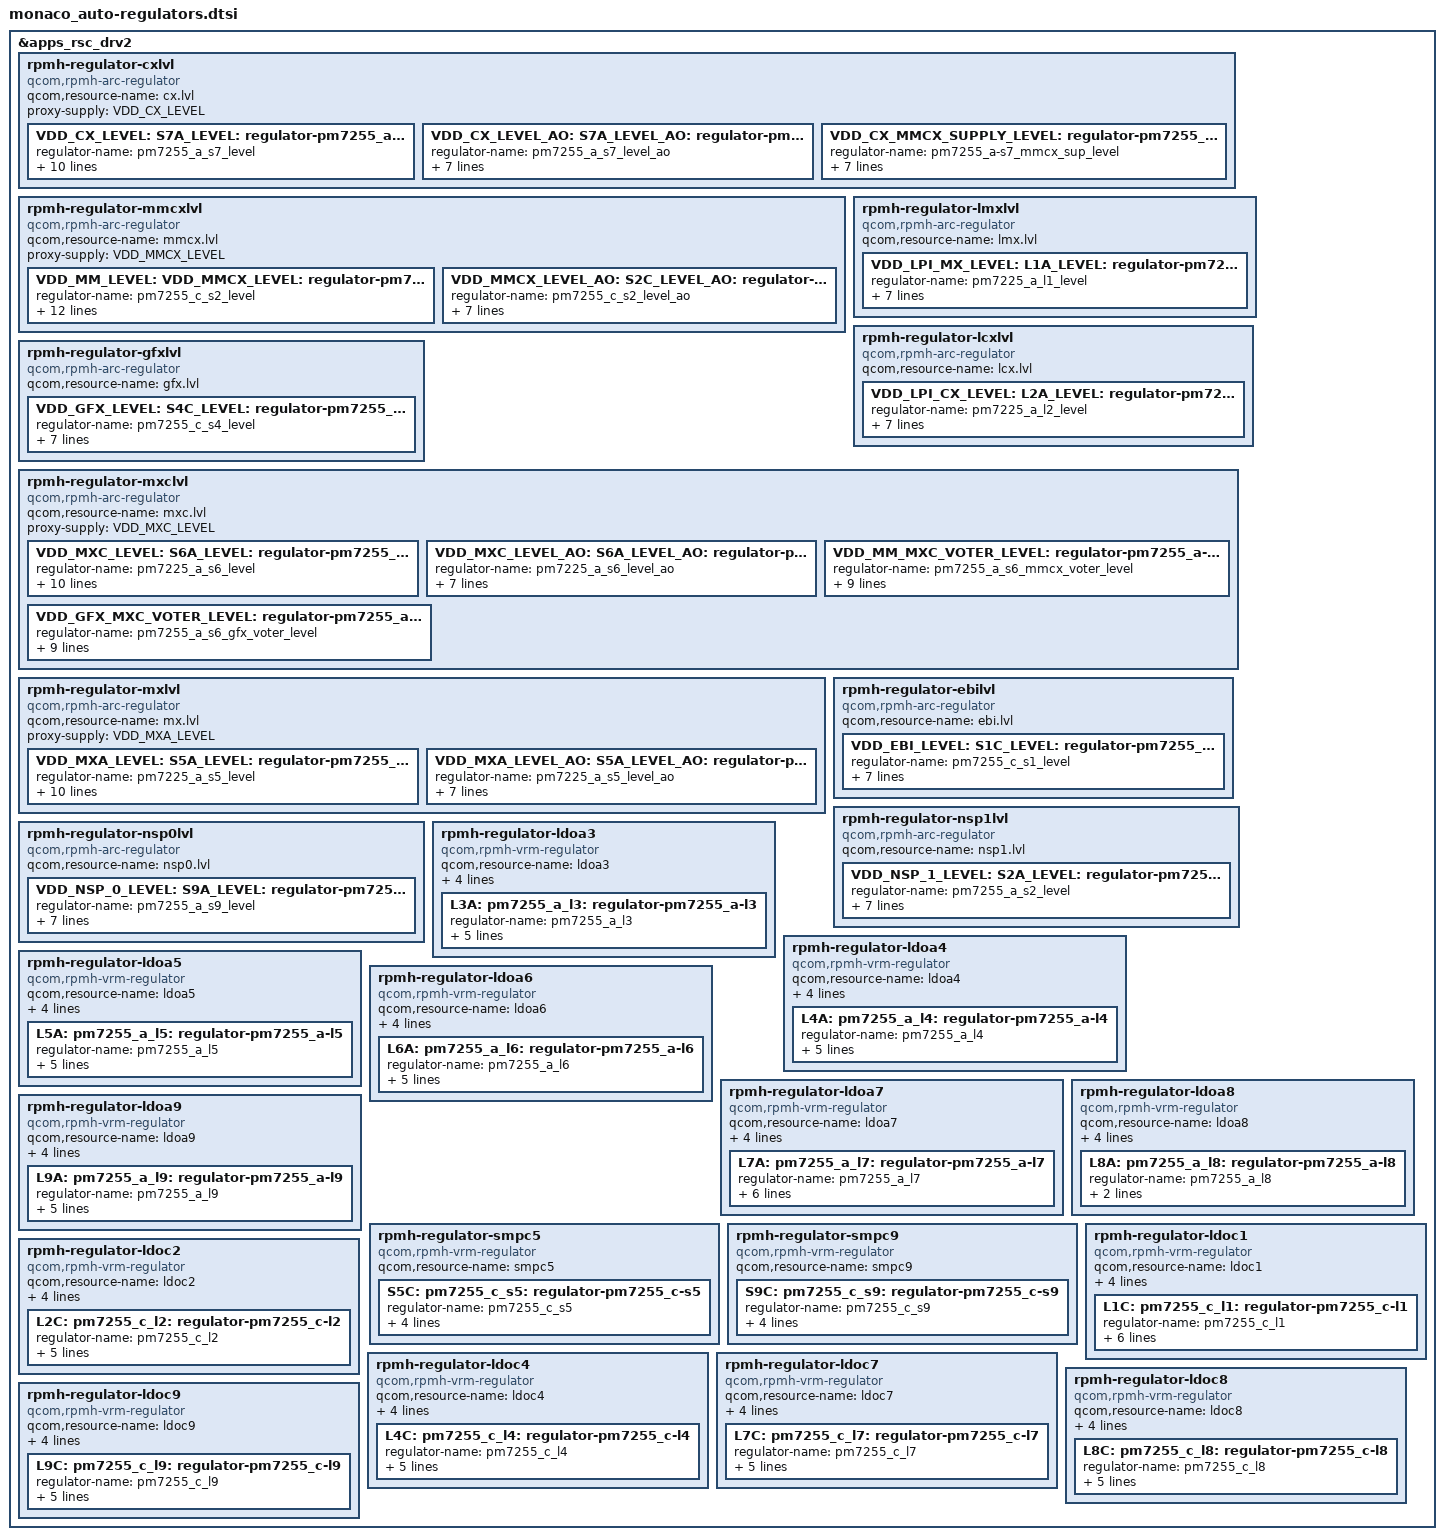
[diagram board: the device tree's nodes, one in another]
#include <dt-bindings/regulator/qcom,rpmh-regulator-levels.h>

&apps_rsc_drv2 {

	rpmh-regulator-cxlvl {
		compatible = "qcom,rpmh-arc-regulator";
		qcom,resource-name = "cx.lvl";
		proxy-supply = <&VDD_CX_LEVEL>;

		VDD_CX_LEVEL: S7A_LEVEL:
		pm7255_a_s7_level: regulator-pm7255_a-s7-level {
			regulator-name = "pm7255_a_s7_level";
			qcom,set = <RPMH_REGULATOR_SET_ALL>;
			regulator-min-microvolt =
				<RPMH_REGULATOR_LEVEL_RETENTION>;
			regulator-max-microvolt =
				<RPMH_REGULATOR_LEVEL_MAX>;
			qcom,init-voltage-level =
				<RPMH_REGULATOR_LEVEL_TURBO>;
			qcom,proxy-consumer-enable;
			qcom,proxy-consumer-voltage =
				<RPMH_REGULATOR_LEVEL_TURBO
				 RPMH_REGULATOR_LEVEL_MAX>;
		};

		VDD_CX_LEVEL_AO: S7A_LEVEL_AO:
		pm7255_a_s7_level_ao: regulator-pm7255_a-s7-level-ao {
			regulator-name = "pm7255_a_s7_level_ao";
			qcom,set = <RPMH_REGULATOR_SET_ACTIVE>;
			regulator-min-microvolt =
				<RPMH_REGULATOR_LEVEL_RETENTION>;
			regulator-max-microvolt =
				<RPMH_REGULATOR_LEVEL_MAX>;
			qcom,init-voltage-level =
				<RPMH_REGULATOR_LEVEL_RETENTION>;
		};

		VDD_CX_MMCX_SUPPLY_LEVEL: regulator-pm7255_a-s7-mmcx-sup-level {
			regulator-name = "pm7255_a-s7_mmcx_sup_level";
			qcom,set = <RPMH_REGULATOR_SET_ALL>;
			regulator-min-microvolt =
				<RPMH_REGULATOR_LEVEL_MIN_SVS>;
			regulator-max-microvolt =
				<RPMH_REGULATOR_LEVEL_MAX>;
			qcom,init-voltage-level =
				<RPMH_REGULATOR_LEVEL_MIN_SVS>;
		};
	};

	rpmh-regulator-mmcxlvl {
		compatible = "qcom,rpmh-arc-regulator";
		qcom,resource-name = "mmcx.lvl";
		proxy-supply = <&VDD_MMCX_LEVEL>;

		VDD_MM_LEVEL: VDD_MMCX_LEVEL: S2C_LEVEL:
		pm7255_c_s2_level: regulator-pm7255_c-s2-level {
			regulator-name = "pm7255_c_s2_level";
			qcom,set = <RPMH_REGULATOR_SET_ALL>;
			pm7255_c_s2_level-parent-supply =
					<&VDD_CX_MMCX_SUPPLY_LEVEL>;
			regulator-min-microvolt =
				<RPMH_REGULATOR_LEVEL_SVS_L1>;
			regulator-max-microvolt =
				<RPMH_REGULATOR_LEVEL_MAX>;
			qcom,init-voltage-level =
				<RPMH_REGULATOR_LEVEL_TURBO>;
			qcom,proxy-consumer-enable;
			qcom,proxy-consumer-voltage =
				<RPMH_REGULATOR_LEVEL_TURBO
				 RPMH_REGULATOR_LEVEL_MAX>;
		};

		VDD_MMCX_LEVEL_AO: S2C_LEVEL_AO:
		pm7255_c_s2_level_ao: regulator-pm7255_c-s2-level-ao {
			regulator-name = "pm7255_c_s2_level_ao";
			qcom,set = <RPMH_REGULATOR_SET_ACTIVE>;
			regulator-min-microvolt =
				<RPMH_REGULATOR_LEVEL_SVS_L1>;
			regulator-max-microvolt =
				<RPMH_REGULATOR_LEVEL_MAX>;
			qcom,init-voltage-level =
				<RPMH_REGULATOR_LEVEL_SVS_L1>;
		};
	};

	rpmh-regulator-lmxlvl {
		compatible = "qcom,rpmh-arc-regulator";
		qcom,resource-name = "lmx.lvl";

		VDD_LPI_MX_LEVEL: L1A_LEVEL:
		pm7255_a_l1_level: regulator-pm7255_a-l1-level {
			regulator-name = "pm7225_a_l1_level";
			qcom,set = <RPMH_REGULATOR_SET_ALL>;
			regulator-min-microvolt =
				<RPMH_REGULATOR_LEVEL_RETENTION>;
			regulator-max-microvolt =
				<RPMH_REGULATOR_LEVEL_MAX>;
			qcom,init-voltage-level =
				<RPMH_REGULATOR_LEVEL_RETENTION>;
		};
	};

	rpmh-regulator-lcxlvl {
		compatible = "qcom,rpmh-arc-regulator";
		qcom,resource-name = "lcx.lvl";

		VDD_LPI_CX_LEVEL: L2A_LEVEL:
		pm7255_a_l2_level: regulator-pm7255_a-l2-level {
			regulator-name = "pm7225_a_l2_level";
			qcom,set = <RPMH_REGULATOR_SET_ALL>;
			regulator-min-microvolt =
				<RPMH_REGULATOR_LEVEL_RETENTION>;
			regulator-max-microvolt =
				<RPMH_REGULATOR_LEVEL_MAX>;
			qcom,init-voltage-level =
				<RPMH_REGULATOR_LEVEL_RETENTION>;
		};
	};

	rpmh-regulator-gfxlvl {
	compatible = "qcom,rpmh-arc-regulator";
	qcom,resource-name = "gfx.lvl";

		VDD_GFX_LEVEL: S4C_LEVEL:
		pm7255_c_s4_level: regulator-pm7255_c-s4-level {
			regulator-name = "pm7255_c_s4_level";
			qcom,set = <RPMH_REGULATOR_SET_ALL>;
			regulator-min-microvolt =
				<RPMH_REGULATOR_LEVEL_SVS_L1>;
			regulator-max-microvolt =
				<RPMH_REGULATOR_LEVEL_MAX>;
			qcom,init-voltage-level =
				<RPMH_REGULATOR_LEVEL_SVS_L1>;
		};
	};

	rpmh-regulator-mxclvl {
		compatible = "qcom,rpmh-arc-regulator";
		qcom,resource-name = "mxc.lvl";
		proxy-supply = <&VDD_MXC_LEVEL>;

		VDD_MXC_LEVEL: S6A_LEVEL:
		pm7255_a_s6_level: regulator-pm7255_a-s6-level {
			regulator-name = "pm7225_a_s6_level";
			qcom,set = <RPMH_REGULATOR_SET_ALL>;
			regulator-min-microvolt =
				<RPMH_REGULATOR_LEVEL_RETENTION>;
			regulator-max-microvolt =
				<RPMH_REGULATOR_LEVEL_MAX>;
			qcom,init-voltage-level =
				<RPMH_REGULATOR_LEVEL_TURBO>;
			qcom,proxy-consumer-enable;
			qcom,proxy-consumer-voltage =
				<RPMH_REGULATOR_LEVEL_TURBO
				 RPMH_REGULATOR_LEVEL_MAX>;
		};

		VDD_MXC_LEVEL_AO: S6A_LEVEL_AO:
		pm7255_a_s6_level_ao: regulator-pm7255_a-s6-level-ao {
			regulator-name = "pm7225_a_s6_level_ao";
			qcom,set = <RPMH_REGULATOR_SET_ACTIVE>;
			regulator-min-microvolt =
				<RPMH_REGULATOR_LEVEL_RETENTION>;
			regulator-max-microvolt =
				<RPMH_REGULATOR_LEVEL_MAX>;
			qcom,init-voltage-level =
				<RPMH_REGULATOR_LEVEL_RETENTION>;
		};

		VDD_MM_MXC_VOTER_LEVEL:
		regulator-pm7255_a-s6-mmcx-voter-level {
			regulator-name = "pm7255_a_s6_mmcx_voter_level";
			pm7255_a_s6_mmcx_voter_level-parent-supply =
				<&VDD_MMCX_LEVEL>;
			qcom,set = <RPMH_REGULATOR_SET_ALL>;
			regulator-min-microvolt =
				<RPMH_REGULATOR_LEVEL_MIN_SVS>;
			regulator-max-microvolt =
				<RPMH_REGULATOR_LEVEL_MAX>;
			qcom,init-voltage-level =
				<RPMH_REGULATOR_LEVEL_MIN_SVS>;
		};

		VDD_GFX_MXC_VOTER_LEVEL:
		regulator-pm7255_a-s6-gfx-voter-level {
			regulator-name = "pm7255_a_s6_gfx_voter_level";
			pm7255_a_s6_gfx_voter_level-parent-supply =
				<&VDD_GFX_LEVEL>;
			qcom,set = <RPMH_REGULATOR_SET_ALL>;
			regulator-min-microvolt =
				<RPMH_REGULATOR_LEVEL_MIN_SVS>;
			regulator-max-microvolt =
				<RPMH_REGULATOR_LEVEL_MAX>;
			qcom,init-voltage-level =
				<RPMH_REGULATOR_LEVEL_MIN_SVS>;
		};
	};

	rpmh-regulator-mxlvl {
		compatible = "qcom,rpmh-arc-regulator";
		qcom,resource-name = "mx.lvl";
		proxy-supply = <&VDD_MXA_LEVEL>;

		VDD_MXA_LEVEL: S5A_LEVEL:
		pm7255_a_s5_level: regulator-pm7255_a-s5-level {
			regulator-name = "pm7225_a_s5_level";
			qcom,set = <RPMH_REGULATOR_SET_ALL>;
			regulator-min-microvolt =
				<RPMH_REGULATOR_LEVEL_RETENTION>;
			regulator-max-microvolt =
				<RPMH_REGULATOR_LEVEL_MAX>;
			qcom,init-voltage-level =
				<RPMH_REGULATOR_LEVEL_TURBO>;
			qcom,proxy-consumer-enable;
			qcom,proxy-consumer-voltage =
				<RPMH_REGULATOR_LEVEL_TURBO
				 RPMH_REGULATOR_LEVEL_MAX>;
		};

		VDD_MXA_LEVEL_AO: S5A_LEVEL_AO:
		pm7255_a_s5_level_ao: regulator-pm7255_a-s5-level-ao {
			regulator-name = "pm7225_a_s5_level_ao";
			qcom,set = <RPMH_REGULATOR_SET_ACTIVE>;
			regulator-min-microvolt =
				<RPMH_REGULATOR_LEVEL_RETENTION>;
			regulator-max-microvolt =
				<RPMH_REGULATOR_LEVEL_MAX>;
			qcom,init-voltage-level =
				<RPMH_REGULATOR_LEVEL_RETENTION>;
		};
	};

	rpmh-regulator-ebilvl {
		compatible = "qcom,rpmh-arc-regulator";
		qcom,resource-name = "ebi.lvl";

		VDD_EBI_LEVEL: S1C_LEVEL:
		pm7255_c_s1_level: regulator-pm7255_c-s1-level {
			regulator-name = "pm7255_c_s1_level";
			qcom,set = <RPMH_REGULATOR_SET_ALL>;
			regulator-min-microvolt =
				<RPMH_REGULATOR_LEVEL_RETENTION>;
			regulator-max-microvolt =
				<RPMH_REGULATOR_LEVEL_MAX>;
			qcom,init-voltage-level =
				<RPMH_REGULATOR_LEVEL_RETENTION>;
		};
	};

	rpmh-regulator-nsp1lvl {
		compatible = "qcom,rpmh-arc-regulator";
		qcom,resource-name = "nsp1.lvl";

		VDD_NSP_1_LEVEL: S2A_LEVEL:
		pm7255_a_s2_level: regulator-pm7255_a-s2-level {
			regulator-name = "pm7255_a_s2_level";
			qcom,set = <RPMH_REGULATOR_SET_ALL>;
			regulator-min-microvolt =
				<RPMH_REGULATOR_LEVEL_SVS_L1>;
			regulator-max-microvolt =
				<RPMH_REGULATOR_LEVEL_MAX>;
			qcom,init-voltage-level =
				<RPMH_REGULATOR_LEVEL_SVS_L1>;
		};
	};

	rpmh-regulator-nsp0lvl {
		compatible = "qcom,rpmh-arc-regulator";
		qcom,resource-name = "nsp0.lvl";

		VDD_NSP_0_LEVEL: S9A_LEVEL:
		pm7255_a_s9_level: regulator-pm7255_a-s9-level {
			regulator-name = "pm7255_a_s9_level";
			qcom,set = <RPMH_REGULATOR_SET_ALL>;
			regulator-min-microvolt =
				<RPMH_REGULATOR_LEVEL_SVS_L1>;
			regulator-max-microvolt =
				<RPMH_REGULATOR_LEVEL_MAX>;
			qcom,init-voltage-level =
				<RPMH_REGULATOR_LEVEL_SVS_L1>;
		};
	};

	rpmh-regulator-ldoa3 {
		compatible = "qcom,rpmh-vrm-regulator";
		qcom,resource-name = "ldoa3";
		qcom,regulator-type = "pmic5-ldo";
		qcom,supported-modes =
			<RPMH_REGULATOR_MODE_LPM
			RPMH_REGULATOR_MODE_HPM>;
		qcom,mode-threshold-currents = <0 30000>;

		L3A:
		pm7255_a_l3: regulator-pm7255_a-l3 {
			regulator-name = "pm7255_a_l3";
			qcom,set = <RPMH_REGULATOR_SET_ALL>;
			regulator-min-microvolt = <1200000>;
			regulator-max-microvolt = <1200000>;
			qcom,init-voltage = <1200000>;
			qcom,init-mode = <RPMH_REGULATOR_MODE_HPM>;
		};
	};

	rpmh-regulator-ldoa4 {
		compatible = "qcom,rpmh-vrm-regulator";
		qcom,resource-name = "ldoa4";
		qcom,regulator-type = "pmic5-ldo";
		qcom,supported-modes =
			<RPMH_REGULATOR_MODE_LPM
			RPMH_REGULATOR_MODE_HPM>;
		qcom,mode-threshold-currents = <0 30000>;

		L4A:
		pm7255_a_l4: regulator-pm7255_a-l4 {
			regulator-name = "pm7255_a_l4";
			qcom,set = <RPMH_REGULATOR_SET_ALL>;
			regulator-min-microvolt = <880000>;
			regulator-max-microvolt = <912000>;
			qcom,init-voltage = <880000>;
			qcom,init-mode = <RPMH_REGULATOR_MODE_HPM>;
		};
	};

	rpmh-regulator-ldoa5 {
		compatible = "qcom,rpmh-vrm-regulator";
		qcom,resource-name = "ldoa5";
		qcom,regulator-type = "pmic5-ldo";
		qcom,supported-modes =
			<RPMH_REGULATOR_MODE_LPM
			RPMH_REGULATOR_MODE_HPM>;
		qcom,mode-threshold-currents = <0 30000>;

		L5A:
		pm7255_a_l5: regulator-pm7255_a-l5 {
			regulator-name = "pm7255_a_l5";
			qcom,set = <RPMH_REGULATOR_SET_ALL>;
			regulator-min-microvolt = <1200000>;
			regulator-max-microvolt = <1200000>;
			qcom,init-voltage = <1200000>;
			qcom,init-mode = <RPMH_REGULATOR_MODE_HPM>;
		};
	};

	rpmh-regulator-ldoa6 {
		compatible = "qcom,rpmh-vrm-regulator";
		qcom,resource-name = "ldoa6";
		qcom,regulator-type = "pmic5-ldo";
		qcom,supported-modes =
			<RPMH_REGULATOR_MODE_LPM
			RPMH_REGULATOR_MODE_HPM>;
		qcom,mode-threshold-currents = <0 30000>;

		L6A:
		pm7255_a_l6: regulator-pm7255_a-l6 {
			regulator-name = "pm7255_a_l6";
			qcom,set = <RPMH_REGULATOR_SET_ALL>;
			regulator-min-microvolt = <880000>;
			regulator-max-microvolt = <912000>;
			qcom,init-voltage = <912000>;
			qcom,init-mode = <RPMH_REGULATOR_MODE_HPM>;
		};
	};

	rpmh-regulator-ldoa7 {
		compatible = "qcom,rpmh-vrm-regulator";
		qcom,resource-name = "ldoa7";
		qcom,regulator-type = "pmic5-ldo";
		qcom,supported-modes =
			<RPMH_REGULATOR_MODE_LPM
			RPMH_REGULATOR_MODE_HPM>;
		qcom,mode-threshold-currents = <0 30000>;

		L7A:
		pm7255_a_l7: regulator-pm7255_a-l7 {
			regulator-name = "pm7255_a_l7";
			qcom,set = <RPMH_REGULATOR_SET_ALL>;
			regulator-min-microvolt = <880000>;
			regulator-max-microvolt = <912000>;
			qcom,init-voltage = <880000>;
			regulator-always-on;
			qcom,init-mode = <RPMH_REGULATOR_MODE_HPM>;
		};
	};

	rpmh-regulator-ldoa8 {
		compatible = "qcom,rpmh-vrm-regulator";
		qcom,resource-name = "ldoa8";
		qcom,regulator-type = "pmic5-ldo";
		qcom,supported-modes =
			<RPMH_REGULATOR_MODE_LPM
			RPMH_REGULATOR_MODE_HPM>;
		qcom,mode-threshold-currents = <0 10000>;

		L8A:
		pm7255_a_l8: regulator-pm7255_a-l8 {
			regulator-name = "pm7255_a_l8";
			qcom,set = <RPMH_REGULATOR_SET_ALL>;
			qcom,init-mode = <RPMH_REGULATOR_MODE_HPM>;
		};
	};

	rpmh-regulator-ldoa9 {
		compatible = "qcom,rpmh-vrm-regulator";
		qcom,resource-name = "ldoa9";
		qcom,regulator-type = "pmic5-ldo";
		qcom,supported-modes =
			<RPMH_REGULATOR_MODE_LPM
			RPMH_REGULATOR_MODE_HPM>;
		qcom,mode-threshold-currents = <0 10000>;

		L9A:
		pm7255_a_l9: regulator-pm7255_a-l9 {
			regulator-name = "pm7255_a_l9";
			qcom,set = <RPMH_REGULATOR_SET_ALL>;
			regulator-min-microvolt = <2970000>;
			regulator-max-microvolt = <3072000>;
			qcom,init-voltage = <3072000>;
			qcom,init-mode = <RPMH_REGULATOR_MODE_HPM>;
		};
	};

	rpmh-regulator-smpc5 {
		compatible = "qcom,rpmh-vrm-regulator";
		qcom,resource-name = "smpc5";

		S5C:
		pm7255_c_s5: regulator-pm7255_c-s5 {
			regulator-name = "pm7255_c_s5";
			qcom,set = <RPMH_REGULATOR_SET_ALL>;
			regulator-min-microvolt = <1100000>;
			regulator-max-microvolt = <1100000>;
			qcom,init-voltage = <1100000>;
		};
	};

	rpmh-regulator-smpc9 {
		compatible = "qcom,rpmh-vrm-regulator";
		qcom,resource-name = "smpc9";

		S9C:
		pm7255_c_s9: regulator-pm7255_c-s9 {
			regulator-name = "pm7255_c_s9";
			qcom,set = <RPMH_REGULATOR_SET_ALL>;
			regulator-min-microvolt = <1352000>;
			regulator-max-microvolt = <1352000>;
			qcom,init-voltage = <1352000>;
		};
	};

	rpmh-regulator-ldoc1 {
		compatible = "qcom,rpmh-vrm-regulator";
		qcom,resource-name = "ldoc1";
		qcom,regulator-type = "pmic5-ldo";
		qcom,supported-modes =
			<RPMH_REGULATOR_MODE_LPM
			RPMH_REGULATOR_MODE_HPM>;
		qcom,mode-threshold-currents = <0 30000>;

		L1C:
		pm7255_c_l1: regulator-pm7255_c-l1 {
			regulator-name = "pm7255_c_l1";
			qcom,set = <RPMH_REGULATOR_SET_ALL>;
			qcom,hpm-min-load = <10000>;
			regulator-min-microvolt = <300000>;
			regulator-max-microvolt = <500000>;
			qcom,init-voltage = <500000>;
			qcom,init-mode = <RPMH_REGULATOR_MODE_HPM>;
		};
	};

	rpmh-regulator-ldoc2 {
		compatible = "qcom,rpmh-vrm-regulator";
		qcom,resource-name = "ldoc2";
		qcom,regulator-type = "pmic5-ldo";
		qcom,supported-modes =
			<RPMH_REGULATOR_MODE_LPM
			RPMH_REGULATOR_MODE_HPM>;
		qcom,mode-threshold-currents = <0 30000>;

		L2C:
		pm7255_c_l2: regulator-pm7255_c-l2 {
			regulator-name = "pm7255_c_l2";
			qcom,set = <RPMH_REGULATOR_SET_ALL>;
			regulator-min-microvolt = <900000>;
			regulator-max-microvolt = <900000>;
			qcom,init-voltage = <900000>;
			qcom,init-mode =
				<RPMH_REGULATOR_MODE_HPM>;
		};
	};

	rpmh-regulator-ldoc4 {
		compatible = "qcom,rpmh-vrm-regulator";
		qcom,resource-name = "ldoc4";
		qcom,regulator-type = "pmic5-ldo";
		qcom,supported-modes =
			<RPMH_REGULATOR_MODE_LPM
			RPMH_REGULATOR_MODE_HPM>;
		qcom,mode-threshold-currents = <0 30000>;

		L4C:
		pm7255_c_l4: regulator-pm7255_c-l4 {
			regulator-name = "pm7255_c_l4";
			qcom,set = <RPMH_REGULATOR_SET_ALL>;
			regulator-min-microvolt = <1200000>;
			regulator-max-microvolt = <1200000>;
			qcom,init-voltage = <1200000>;
			qcom,init-mode = <RPMH_REGULATOR_MODE_HPM>;
		};
	};

	rpmh-regulator-ldoc7 {
		compatible = "qcom,rpmh-vrm-regulator";
		qcom,resource-name = "ldoc7";
		qcom,regulator-type = "pmic5-ldo";
		qcom,supported-modes =
			<RPMH_REGULATOR_MODE_LPM
			RPMH_REGULATOR_MODE_HPM>;
		qcom,mode-threshold-currents = <0 30000>;

		L7C:
		pm7255_c_l7: regulator-pm7255_c-l7 {
			regulator-name = "pm7255_c_l7";
			qcom,set = <RPMH_REGULATOR_SET_ALL>;
			regulator-min-microvolt = <1800000>;
			regulator-max-microvolt = <1800000>;
			qcom,init-voltage = <1800000>;
			qcom,init-mode = <RPMH_REGULATOR_MODE_HPM>;
		};
	};

	rpmh-regulator-ldoc8 {
		compatible = "qcom,rpmh-vrm-regulator";
		qcom,resource-name = "ldoc8";
		qcom,regulator-type = "pmic5-ldo";
		qcom,supported-modes =
			<RPMH_REGULATOR_MODE_LPM
			RPMH_REGULATOR_MODE_HPM>;
		qcom,mode-threshold-currents = <0 10000>;

		L8C:
		pm7255_c_l8: regulator-pm7255_c-l8 {
			regulator-name = "pm7255_c_l8";
			qcom,set = <RPMH_REGULATOR_SET_ALL>;
			regulator-min-microvolt = <1800000>;
			regulator-max-microvolt = <1800000>;
			qcom,init-voltage = <1800000>;
			qcom,init-mode = <RPMH_REGULATOR_MODE_HPM>;
		};
	};

	rpmh-regulator-ldoc9 {
		compatible = "qcom,rpmh-vrm-regulator";
		qcom,resource-name = "ldoc9";
		qcom,regulator-type = "pmic5-ldo";
		qcom,supported-modes =
			<RPMH_REGULATOR_MODE_LPM
			RPMH_REGULATOR_MODE_HPM>;
		qcom,mode-threshold-currents = <0 10000>;

		L9C:
		pm7255_c_l9: regulator-pm7255_c-l9 {
			regulator-name = "pm7255_c_l9";
			qcom,set = <RPMH_REGULATOR_SET_ALL>;
			regulator-min-microvolt = <1800000>;
			regulator-max-microvolt = <1800000>;
			qcom,init-voltage = <1800000>;
			qcom,init-mode = <RPMH_REGULATOR_MODE_HPM>;
		};
	};
};
